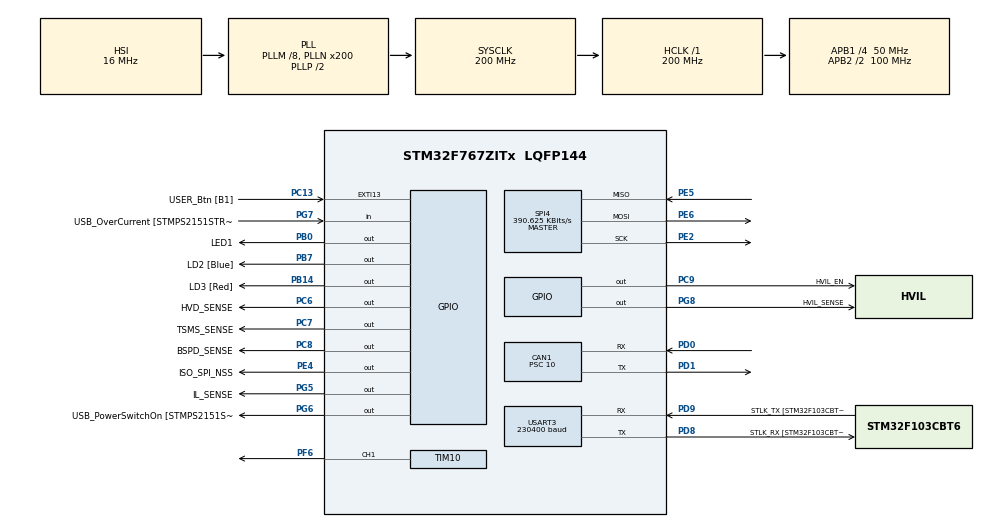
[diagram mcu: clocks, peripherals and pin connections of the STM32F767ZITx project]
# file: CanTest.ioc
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CAN1.BS1=CAN_BS1_8TQ
CAN1.CalculateBaudRate=500000
CAN1.CalculateTimeBit=2000.00
CAN1.CalculateTimeQuantum=200.0
CAN1.Mode=CAN_MODE_LOOPBACK
CAN1.Prescaler=10
CAN1.SJW=CAN_SJW_1TQ
Dma.Request0=USART3_RX
Dma.USART3_RX.0.Direction=DMA_PERIPH_TO_MEMORY
Dma.USART3_RX.0.FIFOMode=DMA_FIFOMODE_DISABLE
Dma.USART3_RX.0.Instance=DMA1_Stream1
Dma.USART3_RX.0.MemDataAlignment=DMA_MDATAALIGN_BYTE
Dma.USART3_RX.0.MemInc=DMA_MINC_ENABLE
Dma.USART3_RX.0.Mode=DMA_CIRCULAR
Dma.USART3_RX.0.PeriphDataAlignment=DMA_PDATAALIGN_BYTE
Dma.USART3_RX.0.PeriphInc=DMA_PINC_DISABLE
Dma.USART3_RX.0.Priority=DMA_PRIORITY_LOW
FREERTOS.MEMORY_ALLOCATION=0
FREERTOS.Tasks01=mainTask,0,1000,mainTaskFunction,As weak,NULL,Dynamic,NULL,NULL;printTaskName,-2,1000,printTask,As external,NULL,Dynamic,NULL,NULL;cliTaskName,-2,1000,cliTask,As external,NULL,Dynamic,NULL,NULL;controlTaskName,0,1000,controlTask,As external,NULL,Dynamic,NULL,NULL;PCDC,0,1000,pcdcTask,As external,NULL,Dynamic,NULL,NULL;BatteryTask,3,1000,batteryTask,As external,NULL,Dynamic,NULL,NULL;sensorTaskName,0,1000,sensorTask,As external,NULL,Dynamic,NULL,NULL;watchdogTaskNam,3,1000,watchdogTask,As external,NULL,Dynamic,NULL,NULL
FREERTOS.configCHECK_FOR_STACK_OVERFLOW=2
FREERTOS.configENABLE_FPU=1
FREERTOS.configGENERATE_RUN_TIME_STATS=1
FREERTOS.configMINIMAL_STACK_SIZE=1000
FREERTOS.configTIMER_QUEUE_LENGTH=4
FREERTOS.configTIMER_TASK_PRIORITY=6
FREERTOS.configTIMER_TASK_STACK_DEPTH=1000
FREERTOS.configTOTAL_HEAP_SIZE=262144
FREERTOS.configUSE_COUNTING_SEMAPHORES=1
FREERTOS.configUSE_STATS_FORMATTING_FUNCTIONS=1
FREERTOS.configUSE_TIMERS=1
FREERTOS.configUSE_TRACE_FACILITY=1
IWDG.Reload=160
Mcu.Family=STM32F7
Mcu.Name=STM32F767ZITx
Mcu.Package=LQFP144
NVIC.CAN1_RX0_IRQn=true\:5\:0\:false\:false\:true\:true\:true\:true
NVIC.CAN1_RX1_IRQn=true\:5\:0\:false\:false\:true\:true\:true\:true
NVIC.CAN1_SCE_IRQn=true\:5\:0\:false\:false\:true\:true\:true\:true
NVIC.CAN1_TX_IRQn=true\:5\:0\:false\:false\:true\:true\:true\:true
NVIC.DMA1_Stream1_IRQn=true\:5\:0\:false\:false\:true\:true\:false\:true
NVIC.PriorityGroup=NVIC_PRIORITYGROUP_4
NVIC.TIM1_UP_TIM10_IRQn=true\:0\:0\:false\:false\:true\:false\:false\:true
NVIC.TimeBase=TIM1_UP_TIM10_IRQn
NVIC.TimeBaseIP=TIM1
NVIC.USART3_IRQn=true\:5\:0\:false\:false\:true\:true\:true\:true
PA1.GPIO_Label=RMII_REF_CLK [LAN8742A-CZ-TR_REFCLK0]
PA1.Signal=ETH_REF_CLK
PA10.GPIO_Label=USB_ID
PA10.Signal=USB_OTG_FS_ID
PA11.GPIO_Label=USB_DM
PA11.Signal=USB_OTG_FS_DM
PA12.GPIO_Label=USB_DP
PA12.Signal=USB_OTG_FS_DP
PA13.GPIO_Label=TMS
PA13.Signal=SYS_JTMS-SWDIO
PA14.GPIO_Label=TCK
PA14.Signal=SYS_JTCK-SWCLK
PA2.GPIO_Label=RMII_MDIO [LAN8742A-CZ-TR_MDIO]
PA2.Signal=ETH_MDIO
PA7.GPIO_Label=RMII_CRS_DV [LAN8742A-CZ-TR_CRS_DV]
PA7.Signal=ETH_CRS_DV
PA8.GPIO_Label=USB_SOF [TP1]
PA8.Signal=USB_OTG_FS_SOF
PA9.GPIO_Label=USB_VBUS
PA9.Signal=USB_OTG_FS_VBUS
PB0.GPIO_Label=LED1
PB0.Signal=GPIO_Output
PB13.GPIO_Label=RMII_TXD1 [LAN8742A-CZ-TR_TXD1]
PB13.Signal=ETH_TXD1
PB14.GPIO_Label=LD3 [Red]
PB14.Signal=GPIO_Output
PB3.GPIO_Label=SW0
PB3.Signal=SYS_JTDO-SWO
PB7.GPIO_Label=LD2 [Blue]
PB7.Signal=GPIO_Output
PC1.GPIO_Label=RMII_MDC [LAN8742A-CZ-TR_MDC]
PC1.Signal=ETH_MDC
PC13.GPIO_Label=USER_Btn [B1]
PC13.Signal=GPXTI13
PC14/OSC32_IN.Signal=RCC_OSC32_IN
PC15/OSC32_OUT.Signal=RCC_OSC32_OUT
PC4.GPIO_Label=RMII_RXD0 [LAN8742A-CZ-TR_RXD0]
PC4.Signal=ETH_RXD0
PC5.GPIO_Label=RMII_RXD1 [LAN8742A-CZ-TR_RXD1]
PC5.Signal=ETH_RXD1
PC6.GPIO_Label=HVD_SENSE
PC6.Signal=GPIO_Output
PC7.GPIO_Label=TSMS_SENSE
PC7.Signal=GPIO_Output
PC8.GPIO_Label=BSPD_SENSE
PC8.Signal=GPIO_Output
PC9.GPIO_Label=HVIL_EN
PC9.Signal=GPIO_Output
PD0.Mode=CAN_Activate
PD0.Signal=CAN1_RX
PD1.Mode=CAN_Activate
PD1.Signal=CAN1_TX
PD8.GPIO_Label=STLK_RX [STM32F103CBT6_PA3]
PD8.Mode=Asynchronous
PD8.Signal=USART3_TX
PD9.GPIO_Label=STLK_TX [STM32F103CBT6_PA2]
PD9.Mode=Asynchronous
PD9.Signal=USART3_RX
PE2.Mode=Full_Duplex_Master
PE2.Signal=SPI4_SCK
PE4.GPIO_Label=ISO_SPI_NSS
PE4.Signal=GPIO_Output
PE5.Mode=Full_Duplex_Master
PE5.Signal=SPI4_MISO
PE6.Mode=Full_Duplex_Master
PE6.Signal=SPI4_MOSI
PF6.Signal=S_TIM10_CH1
PG11.GPIO_Label=RMII_TX_EN [LAN8742A-CZ-TR_TXEN]
PG11.Signal=ETH_TX_EN
PG13.GPIO_Label=RMII_TXD0 [LAN8742A-CZ-TR_TXD0]
PG13.Signal=ETH_TXD0
PG5.GPIO_Label=IL_SENSE
PG5.Signal=GPIO_Output
PG6.GPIO_Label=USB_PowerSwitchOn [STMPS2151STR_EN]
PG6.Signal=GPIO_Output
PG7.GPIO_Label=USB_OverCurrent [STMPS2151STR_FAULT]
PG7.Signal=GPIO_Input
PG8.GPIO_Label=HVIL_SENSE
PG8.Signal=GPIO_Output
PH0/OSC_IN.GPIO_Label=MCO [STM32F103CBT6_PA8]
PH0/OSC_IN.Signal=RCC_OSC_IN
PH1/OSC_OUT.Signal=RCC_OSC_OUT
ProjectManager.HeapSize=0x200
ProjectManager.StackSize=0x400
ProjectManager.TargetToolchain=Makefile
RCC.48MHZClocksFreq_Value=24000000
RCC.AHBFreq_Value=200000000
RCC.APB1CLKDivider=RCC_HCLK_DIV4
RCC.APB1Freq_Value=50000000
RCC.APB1TimFreq_Value=100000000
RCC.APB2CLKDivider=RCC_HCLK_DIV2
RCC.APB2Freq_Value=100000000
RCC.APB2TimFreq_Value=200000000
RCC.CortexFreq_Value=200000000
RCC.HCLKFreq_Value=200000000
RCC.HSE_VALUE=16000000
RCC.HSI_VALUE=16000000
RCC.LSE_VALUE=32768
RCC.PLLM=8
RCC.PLLMUL=RCC_PLL_MUL9
RCC.PLLN=200
RCC.PRESCALERUSB=RCC_USBCLKSOURCE_PLL_DIV1_5
RCC.SYSCLKFreq_VALUE=200000000
RCC.SYSCLKSource=RCC_SYSCLKSOURCE_PLLCLK
RCC.SYSCLKSourceVirtual=RCC_SYSCLKSOURCE_PLLCLK
RCC.USBFreq_Value=200000000
RCC.VCOOutputFreq_Value=400000000
SH.S_TIM10_CH1.0=TIM10_CH1,PWM Generation1 CH1
SPI4.BaudRatePrescaler=SPI_BAUDRATEPRESCALER_256
SPI4.CLKPhase=SPI_PHASE_2EDGE
SPI4.CLKPolarity=SPI_POLARITY_HIGH
SPI4.CalculateBaudRate=390.625 KBits/s
SPI4.DataSize=SPI_DATASIZE_8BIT
SPI4.Direction=SPI_DIRECTION_2LINES
SPI4.Mode=SPI_MODE_MASTER
SPI4.VirtualType=VM_MASTER
TIM10.Channel=TIM_CHANNEL_1
TIM10.Period=400
TIM10.Prescaler=9
TIM10.Pulse=500
TIM3.Period=65535
USART3.BaudRate=230400
USART3.VirtualMode-Asynchronous=VM_ASYNC
USART3.WordLength=WORDLENGTH_8B
VP_FREERTOS_VS_CMSIS_V1.Mode=CMSIS_V1
VP_IWDG_VS_IWDG.Mode=IWDG_Activate
VP_SYS_VS_tim1.Mode=TIM1
VP_TIM10_VS_ClockSourceINT.Mode=Enable_Timer
VP_TIM3_VS_ClockSourceINT.Mode=Internal
board=NUCLEO-F767ZI

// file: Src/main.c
/* USER CODE BEGIN Header */
/**
  ******************************************************************************
  * @file           : main.c
  * @brief          : Main program body
  ******************************************************************************
  * @attention
  *
  * <h2><center>&copy; Copyright (c) 2021 STMicroelectronics.
  * All rights reserved.</center></h2>
  *
  * This software component is licensed by ST under Ultimate Liberty license
  * SLA0044, the "License"; You may not use this file except in compliance with
  * the License. You may obtain a copy of the License at:
  *                             www.st.com/SLA0044
  *
  ******************************************************************************
  */
/* USER CODE END Header */
#include "main.h"
#include "cmsis_os.h"
#include "can.h"
#include "dma.h"
#include "iwdg.h"
#include "spi.h"
#include "tim.h"
#include "usart.h"
#include "gpio.h"

/* USER CODE BEGIN Includes */
#include "watchdog.h"
#include "generalErrorHandler.h"
/* USER CODE END Includes */

/* USER CODE BEGIN PV */
/* Private variables ---------------------------------------------------------*/

/* USER CODE END PV */

void SystemClock_Config(void);
void MX_FREERTOS_Init(void);
/* USER CODE BEGIN PFP */
/* Private function prototypes -----------------------------------------------*/
__weak void userInit() {}
/* USER CODE END PFP */

int main(void)
{
  /* USER CODE BEGIN 1 */
   checkForWDReset();
  /* USER CODE END 1 */

  /* MCU Configuration--------------------------------------------------------*/

  /* Reset of all peripherals, Initializes the Flash interface and the Systick. */
  HAL_Init();

  /* Configure the system clock */
  SystemClock_Config();

  /* Initialize all configured peripherals */
  MX_GPIO_Init();
  MX_DMA_Init();
  MX_CAN1_Init();
  MX_USART3_UART_Init();
  MX_TIM3_Init();
  MX_IWDG_Init();
  MX_SPI4_Init();
  MX_TIM10_Init();
  /* USER CODE BEGIN 2 */
  userInit();
  printWDResetState();
  handleWatchdogReset();
  /* USER CODE END 2 */

  /* Call init function for freertos objects (in freertos.c) */
  MX_FREERTOS_Init();
  /* Start scheduler */
  osKernelStart();

  /* We should never get here as control is now taken by the scheduler */
  /* Infinite loop */
  while (1)
  {

  }
}

void SystemClock_Config(void)
{
  RCC_OscInitTypeDef RCC_OscInitStruct = {0};
  RCC_ClkInitTypeDef RCC_ClkInitStruct = {0};
  RCC_PeriphCLKInitTypeDef PeriphClkInitStruct = {0};

  /** Configure the main internal regulator output voltage
  */
  __HAL_RCC_PWR_CLK_ENABLE();
  __HAL_PWR_VOLTAGESCALING_CONFIG(PWR_REGULATOR_VOLTAGE_SCALE1);
  /** Initializes the RCC Oscillators according to the specified parameters
  * in the RCC_OscInitTypeDef structure.
  */
  RCC_OscInitStruct.OscillatorType = RCC_OSCILLATORTYPE_HSI|RCC_OSCILLATORTYPE_LSI;
  RCC_OscInitStruct.HSIState = RCC_HSI_ON;
  RCC_OscInitStruct.HSICalibrationValue = RCC_HSICALIBRATION_DEFAULT;
  RCC_OscInitStruct.LSIState = RCC_LSI_ON;
  RCC_OscInitStruct.PLL.PLLState = RCC_PLL_ON;
  RCC_OscInitStruct.PLL.PLLSource = RCC_PLLSOURCE_HSI;
  RCC_OscInitStruct.PLL.PLLM = 8;
  RCC_OscInitStruct.PLL.PLLN = 200;
  RCC_OscInitStruct.PLL.PLLP = RCC_PLLP_DIV2;
  RCC_OscInitStruct.PLL.PLLQ = 2;
  if (HAL_RCC_OscConfig(&RCC_OscInitStruct) != HAL_OK)
  {
    Error_Handler();
  }
  /** Activate the Over-Drive mode
  */
  if (HAL_PWREx_EnableOverDrive() != HAL_OK)
  {
    Error_Handler();
  }
  /** Initializes the CPU, AHB and APB buses clocks
  */
  RCC_ClkInitStruct.ClockType = RCC_CLOCKTYPE_HCLK|RCC_CLOCKTYPE_SYSCLK
                              |RCC_CLOCKTYPE_PCLK1|RCC_CLOCKTYPE_PCLK2;
  RCC_ClkInitStruct.SYSCLKSource = RCC_SYSCLKSOURCE_PLLCLK;
  RCC_ClkInitStruct.AHBCLKDivider = RCC_SYSCLK_DIV1;
  RCC_ClkInitStruct.APB1CLKDivider = RCC_HCLK_DIV4;
  RCC_ClkInitStruct.APB2CLKDivider = RCC_HCLK_DIV2;

  if (HAL_RCC_ClockConfig(&RCC_ClkInitStruct, FLASH_LATENCY_6) != HAL_OK)
  {
    Error_Handler();
  }
  PeriphClkInitStruct.PeriphClockSelection = RCC_PERIPHCLK_USART3;
  PeriphClkInitStruct.Usart3ClockSelection = RCC_USART3CLKSOURCE_PCLK1;
  if (HAL_RCCEx_PeriphCLKConfig(&PeriphClkInitStruct) != HAL_OK)
  {
    Error_Handler();
  }
}

 /**
  * @brief  Period elapsed callback in non blocking mode
  * @note   This function is called  when TIM1 interrupt took place, inside
  * HAL_TIM_IRQHandler(). It makes a direct call to HAL_IncTick() to increment
  * a global variable "uwTick" used as application time base.
  * @param  htim : TIM handle
  * @retval None
  */
void HAL_TIM_PeriodElapsedCallback(TIM_HandleTypeDef *htim)
{
  if (htim->Instance == TIM1) {
    HAL_IncTick();
  }
}

void Error_Handler(void)
{
  /* USER CODE BEGIN Error_Handler_Debug */
  /* User can add his own implementation to report the HAL error return state */
  while(1)
  {
	_handleError(__FILE__, __LINE__);
  }
  /* USER CODE END Error_Handler_Debug */
}

/************************ (C) COPYRIGHT STMicroelectronics *****END OF FILE****/

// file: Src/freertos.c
/* USER CODE BEGIN Header */
/**
  ******************************************************************************
  * File Name          : freertos.c
  * Description        : Code for freertos applications
  ******************************************************************************
  * @attention
  *
  * <h2><center>&copy; Copyright (c) 2021 STMicroelectronics.
  * All rights reserved.</center></h2>
  *
  * This software component is licensed by ST under Ultimate Liberty license
  * SLA0044, the "License"; You may not use this file except in compliance with
  * the License. You may obtain a copy of the License at:
  *                             www.st.com/SLA0044
  *
  ******************************************************************************
  */
/* USER CODE END Header */

#include "FreeRTOS.h"
#include "task.h"
#include "main.h"
#include "cmsis_os.h"

/* USER CODE BEGIN Includes */
#include "stm32f7xx_hal.h"

/* USER CODE END Includes */

osThreadId mainTaskHandle;
osThreadId printTaskNameHandle;
osThreadId cliTaskNameHandle;
osThreadId controlTaskNameHandle;
osThreadId PCDCHandle;
osThreadId BatteryTaskHandle;
osThreadId sensorTaskNameHandle;
osThreadId watchdogTaskNamHandle;

void mainTaskFunction(void const * argument);
extern void printTask(void const * argument);
extern void cliTask(void const * argument);
extern void controlTask(void const * argument);
extern void pcdcTask(void const * argument);
extern void batteryTask(void const * argument);
extern void sensorTask(void const * argument);
extern void watchdogTask(void const * argument);

void MX_FREERTOS_Init(void); /* (MISRA C 2004 rule 8.1) */

/* Hook prototypes */
void configureTimerForRunTimeStats(void);
unsigned long getRunTimeCounterValue(void);
void vApplicationStackOverflowHook(xTaskHandle xTask, signed char *pcTaskName);

/* USER CODE BEGIN 1 */
/* Functions needed when configGENERATE_RUN_TIME_STATS is on */
__weak void configureTimerForRunTimeStats(void)
{

}

__weak unsigned long getRunTimeCounterValue(void)
{
return 0;
}
/* USER CODE END 1 */

/* USER CODE BEGIN 4 */
__weak void vApplicationStackOverflowHook(xTaskHandle xTask, signed char *pcTaskName)
{
   /* Run time stack overflow checking is performed if
   configCHECK_FOR_STACK_OVERFLOW is defined to 1 or 2. This hook function is
   called if a stack overflow is detected. */
}
/* USER CODE END 4 */

void MX_FREERTOS_Init(void) {

  /* Create the thread(s) */
  /* definition and creation of mainTask */
  osThreadDef(mainTask, mainTaskFunction, osPriorityNormal, 0, 1000);
  mainTaskHandle = osThreadCreate(osThread(mainTask), NULL);

  /* definition and creation of printTaskName */
  osThreadDef(printTaskName, printTask, osPriorityLow, 0, 1000);
  printTaskNameHandle = osThreadCreate(osThread(printTaskName), NULL);

  /* definition and creation of cliTaskName */
  osThreadDef(cliTaskName, cliTask, osPriorityLow, 0, 1000);
  cliTaskNameHandle = osThreadCreate(osThread(cliTaskName), NULL);

  /* definition and creation of controlTaskName */
  osThreadDef(controlTaskName, controlTask, osPriorityNormal, 0, 1000);
  controlTaskNameHandle = osThreadCreate(osThread(controlTaskName), NULL);

  /* definition and creation of PCDC */
  osThreadDef(PCDC, pcdcTask, osPriorityNormal, 0, 1000);
  PCDCHandle = osThreadCreate(osThread(PCDC), NULL);

  /* definition and creation of BatteryTask */
  osThreadDef(BatteryTask, batteryTask, osPriorityRealtime, 0, 1000);
  BatteryTaskHandle = osThreadCreate(osThread(BatteryTask), NULL);

  /* definition and creation of sensorTaskName */
  osThreadDef(sensorTaskName, sensorTask, osPriorityNormal, 0, 1000);
  sensorTaskNameHandle = osThreadCreate(osThread(sensorTaskName), NULL);

  /* definition and creation of watchdogTaskNam */
  osThreadDef(watchdogTaskNam, watchdogTask, osPriorityRealtime, 0, 1000);
  watchdogTaskNamHandle = osThreadCreate(osThread(watchdogTaskNam), NULL);

}

__weak void mainTaskFunction(void const * argument)
{
  for(;;)
  {
    osDelay(1);
  }
}

/************************ (C) COPYRIGHT STMicroelectronics *****END OF FILE****/
